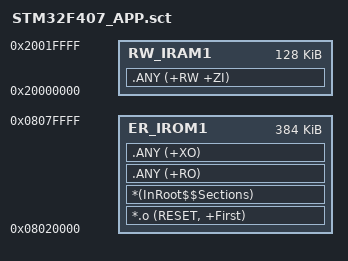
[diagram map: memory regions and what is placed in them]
; *************************************************************
; *** Scatter-Loading Description File for SmartWatch APP   ***
; *** Target: Sector 5~7 (0x08020000, 384 KB)               ***
; *** SRAM:   0x20000000 (128 KB)                           ***
; *************************************************************

LR_IROM1 0x08020000 0x00060000  {    ; load region size_region (384 KB)
  ER_IROM1 0x08020000 0x00060000  {  ; load address = execution address
   *.o (RESET, +First)
   *(InRoot$$Sections)
   .ANY (+RO)
   .ANY (+XO)
  }
  RW_IRAM1 0x20000000 0x00020000  {  ; RW data
   .ANY (+RW +ZI)
  }
}
